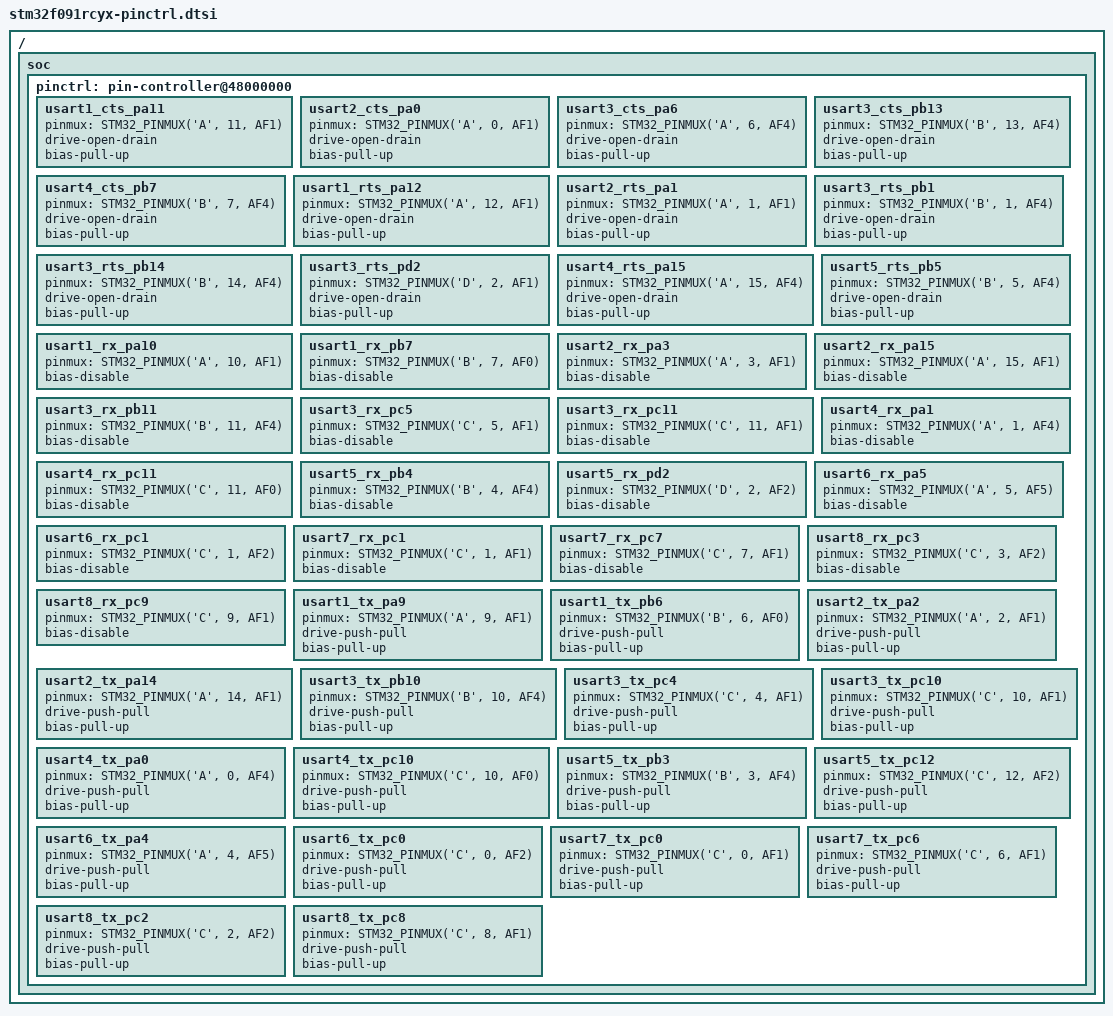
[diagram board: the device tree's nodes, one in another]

/*
 * NOTE: Autogenerated file using stm32_pinctrl_gen.py
 *
 * SPDX-License-Identifier: Apache-2.0
 */

#include <dt-bindings/pinctrl/stm32-pinctrl.h>

/ {
	soc {
		pinctrl: pin-controller@48000000 {
			/* UART_CTS */
			usart1_cts_pa11: usart1_cts_pa11 {
				pinmux = <STM32_PINMUX('A', 11, AF1)>;
				drive-open-drain;
				bias-pull-up;
			};

			usart2_cts_pa0: usart2_cts_pa0 {
				pinmux = <STM32_PINMUX('A', 0, AF1)>;
				drive-open-drain;
				bias-pull-up;
			};

			usart3_cts_pa6: usart3_cts_pa6 {
				pinmux = <STM32_PINMUX('A', 6, AF4)>;
				drive-open-drain;
				bias-pull-up;
			};

			usart3_cts_pb13: usart3_cts_pb13 {
				pinmux = <STM32_PINMUX('B', 13, AF4)>;
				drive-open-drain;
				bias-pull-up;
			};

			usart4_cts_pb7: usart4_cts_pb7 {
				pinmux = <STM32_PINMUX('B', 7, AF4)>;
				drive-open-drain;
				bias-pull-up;
			};


			/* UART_RTS */
			usart1_rts_pa12: usart1_rts_pa12 {
				pinmux = <STM32_PINMUX('A', 12, AF1)>;
				drive-open-drain;
				bias-pull-up;
			};

			usart2_rts_pa1: usart2_rts_pa1 {
				pinmux = <STM32_PINMUX('A', 1, AF1)>;
				drive-open-drain;
				bias-pull-up;
			};

			usart3_rts_pb1: usart3_rts_pb1 {
				pinmux = <STM32_PINMUX('B', 1, AF4)>;
				drive-open-drain;
				bias-pull-up;
			};

			usart3_rts_pb14: usart3_rts_pb14 {
				pinmux = <STM32_PINMUX('B', 14, AF4)>;
				drive-open-drain;
				bias-pull-up;
			};

			usart3_rts_pd2: usart3_rts_pd2 {
				pinmux = <STM32_PINMUX('D', 2, AF1)>;
				drive-open-drain;
				bias-pull-up;
			};

			usart4_rts_pa15: usart4_rts_pa15 {
				pinmux = <STM32_PINMUX('A', 15, AF4)>;
				drive-open-drain;
				bias-pull-up;
			};

			usart5_rts_pb5: usart5_rts_pb5 {
				pinmux = <STM32_PINMUX('B', 5, AF4)>;
				drive-open-drain;
				bias-pull-up;
			};


			/* UART_RX */
			usart1_rx_pa10: usart1_rx_pa10 {
				pinmux = <STM32_PINMUX('A', 10, AF1)>;
				bias-disable;
			};

			usart1_rx_pb7: usart1_rx_pb7 {
				pinmux = <STM32_PINMUX('B', 7, AF0)>;
				bias-disable;
			};

			usart2_rx_pa3: usart2_rx_pa3 {
				pinmux = <STM32_PINMUX('A', 3, AF1)>;
				bias-disable;
			};

			usart2_rx_pa15: usart2_rx_pa15 {
				pinmux = <STM32_PINMUX('A', 15, AF1)>;
				bias-disable;
			};

			usart3_rx_pb11: usart3_rx_pb11 {
				pinmux = <STM32_PINMUX('B', 11, AF4)>;
				bias-disable;
			};

			usart3_rx_pc5: usart3_rx_pc5 {
				pinmux = <STM32_PINMUX('C', 5, AF1)>;
				bias-disable;
			};

			usart3_rx_pc11: usart3_rx_pc11 {
				pinmux = <STM32_PINMUX('C', 11, AF1)>;
				bias-disable;
			};

			usart4_rx_pa1: usart4_rx_pa1 {
				pinmux = <STM32_PINMUX('A', 1, AF4)>;
				bias-disable;
			};

			usart4_rx_pc11: usart4_rx_pc11 {
				pinmux = <STM32_PINMUX('C', 11, AF0)>;
				bias-disable;
			};

			usart5_rx_pb4: usart5_rx_pb4 {
				pinmux = <STM32_PINMUX('B', 4, AF4)>;
				bias-disable;
			};

			usart5_rx_pd2: usart5_rx_pd2 {
				pinmux = <STM32_PINMUX('D', 2, AF2)>;
				bias-disable;
			};

			usart6_rx_pa5: usart6_rx_pa5 {
				pinmux = <STM32_PINMUX('A', 5, AF5)>;
				bias-disable;
			};

			usart6_rx_pc1: usart6_rx_pc1 {
				pinmux = <STM32_PINMUX('C', 1, AF2)>;
				bias-disable;
			};

			usart7_rx_pc1: usart7_rx_pc1 {
				pinmux = <STM32_PINMUX('C', 1, AF1)>;
				bias-disable;
			};

			usart7_rx_pc7: usart7_rx_pc7 {
				pinmux = <STM32_PINMUX('C', 7, AF1)>;
				bias-disable;
			};

			usart8_rx_pc3: usart8_rx_pc3 {
				pinmux = <STM32_PINMUX('C', 3, AF2)>;
				bias-disable;
			};

			usart8_rx_pc9: usart8_rx_pc9 {
				pinmux = <STM32_PINMUX('C', 9, AF1)>;
				bias-disable;
			};


			/* UART_TX */
			usart1_tx_pa9: usart1_tx_pa9 {
				pinmux = <STM32_PINMUX('A', 9, AF1)>;
				drive-push-pull;
				bias-pull-up;
			};

			usart1_tx_pb6: usart1_tx_pb6 {
				pinmux = <STM32_PINMUX('B', 6, AF0)>;
				drive-push-pull;
				bias-pull-up;
			};

			usart2_tx_pa2: usart2_tx_pa2 {
				pinmux = <STM32_PINMUX('A', 2, AF1)>;
				drive-push-pull;
				bias-pull-up;
			};

			usart2_tx_pa14: usart2_tx_pa14 {
				pinmux = <STM32_PINMUX('A', 14, AF1)>;
				drive-push-pull;
				bias-pull-up;
			};

			usart3_tx_pb10: usart3_tx_pb10 {
				pinmux = <STM32_PINMUX('B', 10, AF4)>;
				drive-push-pull;
				bias-pull-up;
			};

			usart3_tx_pc4: usart3_tx_pc4 {
				pinmux = <STM32_PINMUX('C', 4, AF1)>;
				drive-push-pull;
				bias-pull-up;
			};

			usart3_tx_pc10: usart3_tx_pc10 {
				pinmux = <STM32_PINMUX('C', 10, AF1)>;
				drive-push-pull;
				bias-pull-up;
			};

			usart4_tx_pa0: usart4_tx_pa0 {
				pinmux = <STM32_PINMUX('A', 0, AF4)>;
				drive-push-pull;
				bias-pull-up;
			};

			usart4_tx_pc10: usart4_tx_pc10 {
				pinmux = <STM32_PINMUX('C', 10, AF0)>;
				drive-push-pull;
				bias-pull-up;
			};

			usart5_tx_pb3: usart5_tx_pb3 {
				pinmux = <STM32_PINMUX('B', 3, AF4)>;
				drive-push-pull;
				bias-pull-up;
			};

			usart5_tx_pc12: usart5_tx_pc12 {
				pinmux = <STM32_PINMUX('C', 12, AF2)>;
				drive-push-pull;
				bias-pull-up;
			};

			usart6_tx_pa4: usart6_tx_pa4 {
				pinmux = <STM32_PINMUX('A', 4, AF5)>;
				drive-push-pull;
				bias-pull-up;
			};

			usart6_tx_pc0: usart6_tx_pc0 {
				pinmux = <STM32_PINMUX('C', 0, AF2)>;
				drive-push-pull;
				bias-pull-up;
			};

			usart7_tx_pc0: usart7_tx_pc0 {
				pinmux = <STM32_PINMUX('C', 0, AF1)>;
				drive-push-pull;
				bias-pull-up;
			};

			usart7_tx_pc6: usart7_tx_pc6 {
				pinmux = <STM32_PINMUX('C', 6, AF1)>;
				drive-push-pull;
				bias-pull-up;
			};

			usart8_tx_pc2: usart8_tx_pc2 {
				pinmux = <STM32_PINMUX('C', 2, AF2)>;
				drive-push-pull;
				bias-pull-up;
			};

			usart8_tx_pc8: usart8_tx_pc8 {
				pinmux = <STM32_PINMUX('C', 8, AF1)>;
				drive-push-pull;
				bias-pull-up;
			};

		};
	};
};
